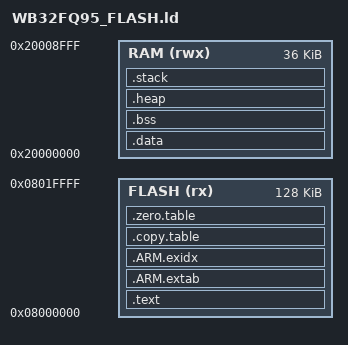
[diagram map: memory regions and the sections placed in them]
/******************************************************************************
 * @file     gcc_arm.ld
 * @brief    GNU Linker Script for WB32FQ95xC (LQFP64)
 *           128KB flash, 36KB SRAM
 *           Stack increased to 0x800, heap to 0x400 for test suite
 ******************************************************************************/

__ROM_BASE = 0x08000000;
__ROM_SIZE = 0x00020000;  /* 128KB */

__RAM_BASE = 0x20000000;
__RAM_SIZE = 0x00009000;  /* 36KB */

__STACK_SIZE = 0x00000800;  /* 2KB stack (increased for printf) */
__HEAP_SIZE  = 0x00000400;  /* 1KB heap */

MEMORY
{
  FLASH (rx)  : ORIGIN = __ROM_BASE, LENGTH = __ROM_SIZE
  RAM   (rwx) : ORIGIN = __RAM_BASE, LENGTH = __RAM_SIZE
}

ENTRY(Reset_Handler)

SECTIONS
{
  .text :
  {
    KEEP(*(.vectors))
    *(.text*)

    KEEP(*(.init))
    KEEP(*(.fini))

    *crtbegin.o(.ctors)
    *crtbegin?.o(.ctors)
    *(EXCLUDE_FILE(*crtend?.o *crtend.o) .ctors)
    *(SORT(.ctors.*))
    *(.ctors)

    *crtbegin.o(.dtors)
    *crtbegin?.o(.dtors)
    *(EXCLUDE_FILE(*crtend?.o *crtend.o) .dtors)
    *(SORT(.dtors.*))
    *(.dtors)

    *(.rodata*)

    KEEP(*(.eh_frame*))
  } > FLASH

  .ARM.extab :
  {
    *(.ARM.extab* .gnu.linkonce.armextab.*)
  } > FLASH

  __exidx_start = .;
  .ARM.exidx :
  {
    *(.ARM.exidx* .gnu.linkonce.armexidx.*)
  } > FLASH
  __exidx_end = .;

  .copy.table :
  {
    . = ALIGN(4);
    __copy_table_start__ = .;
    LONG (__etext)
    LONG (__data_start__)
    LONG (__data_end__ - __data_start__)
    __copy_table_end__ = .;
  } > FLASH

  .zero.table :
  {
    . = ALIGN(4);
    __zero_table_start__ = .;
    LONG (__bss_start__)
    LONG (__bss_end__ - __bss_start__)
    __zero_table_end__ = .;
  } > FLASH

  __etext = ALIGN (4);

  .data : AT (__etext)
  {
    __data_start__ = .;
    *(vtable)
    *(.data)
    *(.data.*)

    . = ALIGN(4);
    PROVIDE_HIDDEN (__preinit_array_start = .);
    KEEP(*(.preinit_array))
    PROVIDE_HIDDEN (__preinit_array_end = .);

    . = ALIGN(4);
    PROVIDE_HIDDEN (__init_array_start = .);
    KEEP(*(SORT(.init_array.*)))
    KEEP(*(.init_array))
    PROVIDE_HIDDEN (__init_array_end = .);

    . = ALIGN(4);
    PROVIDE_HIDDEN (__fini_array_start = .);
    KEEP(*(SORT(.fini_array.*)))
    KEEP(*(.fini_array))
    PROVIDE_HIDDEN (__fini_array_end = .);

    KEEP(*(.jcr*))
    . = ALIGN(4);
    __data_end__ = .;

  } > RAM

  .bss :
  {
    . = ALIGN(4);
    __bss_start__ = .;
    *(.bss)
    *(.bss.*)
    *(COMMON)
    . = ALIGN(4);
    __bss_end__ = .;
  } > RAM AT > RAM

  .heap (COPY) :
  {
    . = ALIGN(8);
    __end__ = .;
    PROVIDE(end = .);
    . = . + __HEAP_SIZE;
    . = ALIGN(8);
    __HeapLimit = .;
  } > RAM

  .stack (ORIGIN(RAM) + LENGTH(RAM) - __STACK_SIZE) (COPY) :
  {
    . = ALIGN(8);
    __StackLimit = .;
    . = . + __STACK_SIZE;
    . = ALIGN(8);
    __StackTop = .;
  } > RAM
  PROVIDE(__stack = __StackTop);

  ASSERT(__StackLimit >= __HeapLimit, "region RAM overflowed with stack")
}
